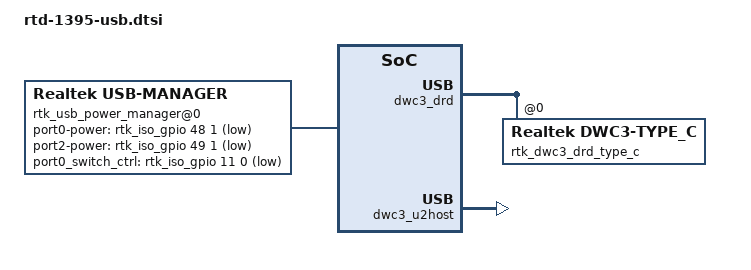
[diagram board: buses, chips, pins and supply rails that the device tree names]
/*
 * realtek,type_c-power-gpio: TypeC power, output, default low
 * realtek,u2host-power-gpio: ehci and u2host power, output, default low
 * realtek,u3host-power-gpio: 1296 u3host power, output, default low
 *
 * usb_iso_mode: ISO mode is only port suspend (Default disable)
 * usb_power_cut: Non ISO mode and power cut (Default disable power cut)
 * Note if enable ISO mode, then power_cut will not effective
 */
/ {
	/include/ "rtd-139x-usb.dtsi"
	rtk_usb_power_manager@0 {
		compatible = "Realtek,usb-manager";
		realtek,port0-power-gpio = <&rtk_iso_gpio 48 1 3>;
		//realtek,port1-power-gpio = <&rtk_iso_gpio 49 1 1>;
		realtek,port2-power-gpio = <&rtk_iso_gpio 49 1 3>;
		realtek,port0_switch_ctrl-gpio = <&rtk_iso_gpio 11 0 1>;

		status = "okay";
	};

	dwc3_drd: rtk_dwc3_drd@98013200 {
		compatible = "Realtek,dwc3";
		status = "okay";

		dwc3_drd@98020000 {
			dr_mode = "peripheral"; /*host, peripheral*/
		};

		rtk_dwc3_drd_type_c@0 {
			compatible = "Realtek,dwc3-type_c";
			drd_mode; //depend on dr_mode = "peripheral"
			status = "okay";
		};
	};

	dwc3_u2host: rtk_dwc3_u2host@98013E00 {
		compatible = "Realtek,dwc3";
		status = "okay";
	};
};
